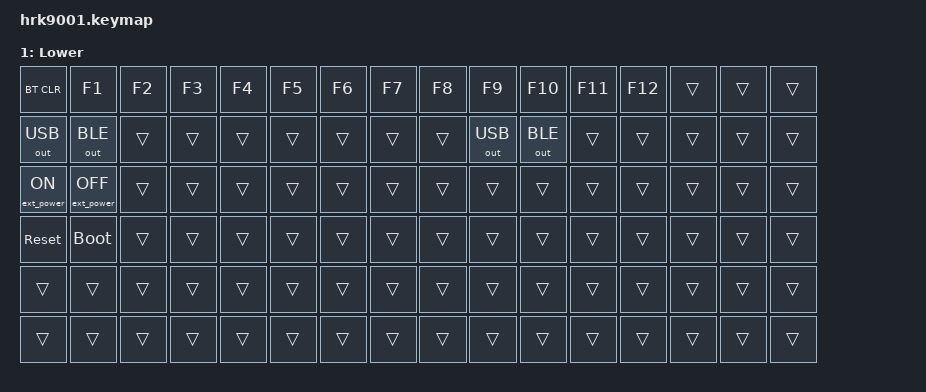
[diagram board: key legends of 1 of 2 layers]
/*
 * Copyright (c) 2020 The ZMK Contributors
 *
 * SPDX-License-Identifier: MIT
 */

#include <behaviors.dtsi>
#include <dt-bindings/zmk/keys.h>
#include <dt-bindings/zmk/bt.h>
#include <dt-bindings/zmk/outputs.h>
#include <dt-bindings/zmk/ext_power.h>
#include <dt-bindings/zmk/rgb.h>

#define DEFAULT 0
#define LOWER   1

/ {
    keymap {
        compatible = "zmk,keymap";

        default_layer {
            label = "Default";
            bindings = <
                &kp ESC     &kp GRAVE   &kp N1     &kp N2     &kp N3     &kp N4     &kp N5     &kp N6         &kp N7     &kp N8     &kp N9     &kp N0     &kp MINUS  &kp EQUAL &trans     &trans     &kp BSPC
                &trans      &kp TAB     &kp Q      &kp W      &kp E      &kp R      &kp T      &kp Y          &kp T      &kp Y      &kp U      &kp I      &kp O      &kp P      &kp LBKT   &kp RBKT   &kp BSLH
                &trans      &kp CAPS    &kp A      &kp S      &kp D      &kp F      &kp G      &kp H          &kp G      &kp H      &kp J      &kp K      &kp L      &kp SEMI   &kp APOS   &kp ENTER  &kp ENTER
                &trans      &kp LSHFT   &kp Z      &kp X      &kp C      &kp V      &kp B      &kp N          &kp B      &kp N      &kp M      &kp COMMA  &kp DOT    &kp SLASH  &kp RSHFT  &kp UP     &trans
                &trans      &kp LCTRL   &trans     &kp LALT   &kp SPACE  &kp SPACE  &kp SPACE  &kp SPACE      &kp SPACE  &kp SPACE  &kp SPACE  &kp RALT   &kp RCTRL  &trans     &kp LEFT   &kp DOWN   &kp RIGHT
            >;
        };

        lower_layer {
            label = "Lower";
            bindings = <
                &bt BT_CLR       &kp F1       &kp F2       &kp F3       &kp F4       &kp F5       &kp F6       &kp F7        &kp F8       &kp F9       &kp F10      &kp F11      &kp F12      &trans       &trans       &trans
                &out OUT_USB     &out OUT_BLE &trans       &trans       &trans       &trans       &trans       &trans        &trans       &out OUT_USB &out OUT_BLE &trans       &trans       &trans       &trans       &trans
                &ext_power EP_ON &ext_power EP_OFF &trans  &trans       &trans       &trans       &trans       &trans        &trans       &trans       &trans       &trans       &trans       &trans       &trans       &trans
                &sys_reset       &bootloader  &trans       &trans       &trans       &trans       &trans       &trans        &trans       &trans       &trans       &trans       &trans       &trans       &trans       &trans
                &trans           &trans       &trans       &trans       &trans       &trans       &trans       &trans        &trans       &trans       &trans       &trans       &trans       &trans       &trans       &trans
                &trans           &trans       &trans       &trans       &trans       &trans       &trans       &trans        &trans       &trans       &trans       &trans       &trans       &trans       &trans       &trans
            >;
        };
    };
};
